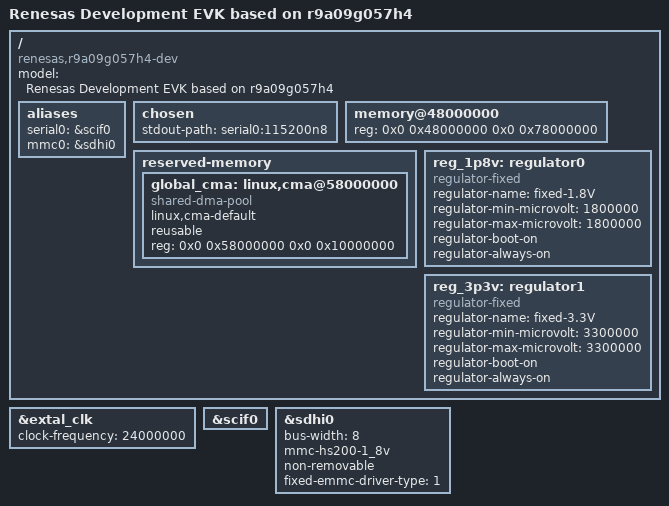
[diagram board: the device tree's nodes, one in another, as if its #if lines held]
// SPDX-License-Identifier: (GPL-2.0-only OR BSD-2-Clause)
/*
 * Device Tree Source for the RZ/V2H Development EVK board
 *
 * Copyright (C) 2022 Renesas Electronics Corp.
 */

/dts-v1/;
#include "r9a09g057.dtsi"
#include <dt-bindings/pinctrl/rzv2h-pinctrl.h>

/*
 * Jumper setting
 *
 * Please change the jumper setting corresponding to below Macros:
 *
 * SW2 (SEL_SD0): 1: eMMC (default);	0: SD
 */

/*
 * There is a conflict between SD0_PWR_EN pin and SD1_CD pins.
 * They all use PA1 pin.
 * So SD0 and SD1 can not be used at the same time.
 * Just only one SDHI interface must be choosen.
 * Macro to select between SDHI0 and SDHI1:
 * SEL_SD0_SD1:	0: SDHI0	1: SDHI1
 *
 * JP7 is a connection between QSD1_CD and PA1 pins.
 * JP7_34 (connect QSD1_CD to PA1):
 *      0 (open):       unconnected
 *      1 (short):      connected
 */

#define SEL_SD0_SD1	0
#if (SEL_SD0_SD1)
#define JP7_34  1
#else
#define SW2	1
#define JP7_34	0
#endif

/ {
	model = "Renesas Development EVK based on r9a09g057h4";
	compatible = "renesas,r9a09g057h4-dev", "renesas,r9a09g057h4", "renesas,r9a09g057";

	aliases {
		serial0 = &scif0;
#if (!SEL_SD0_SD1)
		mmc0 = &sdhi0;
#else
		mmc1 = &sdhi1;
#endif
	};

        chosen {
                stdout-path = "serial0:115200n8";
        };

	memory@48000000 {
		device_type = "memory";
		/* first 128MB is reserved for secure area. */
		reg = <0x0 0x48000000 0x0 0x78000000>;
	};

	reserved-memory {
		#address-cells = <2>;
		#size-cells = <2>;
		ranges;

		global_cma: linux,cma@58000000 {
			compatible = "shared-dma-pool";
			linux,cma-default;
			reusable;
			reg = <0x0 0x58000000 0x0 0x10000000>;
		};
	};

	reg_1p8v: regulator0 {
		compatible = "regulator-fixed";

		regulator-name = "fixed-1.8V";
		regulator-min-microvolt = <1800000>;
		regulator-max-microvolt = <1800000>;
		regulator-boot-on;
		regulator-always-on;
	};

	reg_3p3v: regulator1 {
		compatible = "regulator-fixed";

		regulator-name = "fixed-3.3V";
		regulator-min-microvolt = <3300000>;
		regulator-max-microvolt = <3300000>;
		regulator-boot-on;
		regulator-always-on;
	};

};

&extal_clk {
	clock-frequency = <24000000>;
};

&scif0 {

	status = "okay";
};

#if (!SEL_SD0_SD1)
#if (SW12)
&sdhi0 {
	bus-width = <8>;
	mmc-hs200-1_8v;
	non-removable;
	fixed-emmc-driver-type = <1>;
	status = "okay";
};
#else
&sdhi0 {

	bus-width = <4>;
	sd-uhs-sdr50;
	sd-uhs-sdr104;
	status = "okay";
};
#endif
#else
&sdhi1 {

	bus-width = <4>;
	sd-uhs-sdr50;
	sd-uhs-sdr104;
	status = "okay";
};
#endif
